# SAC0_455.0.8_config4 register map
Vendor: Texas Instruments
Peripheral module from a debugger description file (folder msp430).
Registers are 16-bit, read-write, no defined reset value unless marked. A register's access mark holds for its fields unless they carry their own. Offsets are as the file gives them; lines under a group give offsets from that group; [hi:lo] are bit positions; {n}, {i} and the like mark numbered series; 'fields as' and 'values as' point back to an identical list; <NAME> marks a mode.

## SAC0
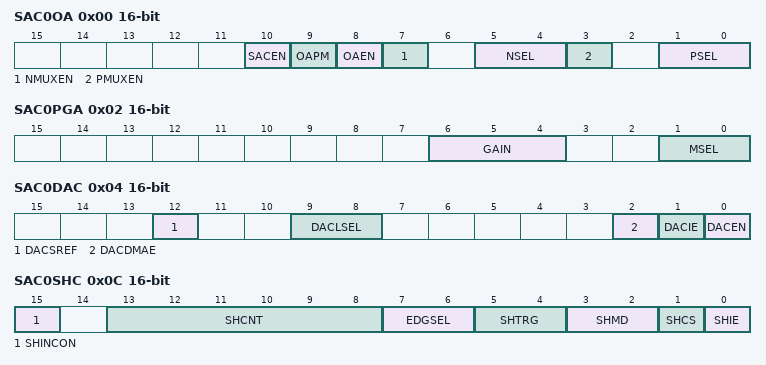
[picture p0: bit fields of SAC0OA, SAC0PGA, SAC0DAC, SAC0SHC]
0x00 SAC0OA — SAC OA Control Register
  [10] SACEN — SAC Enable selection
    0=SAC all modules are disabled, then the SAC output high impedance; 1=SAC all modules are enabled, normal mode
  [9] OAPM — SAC OA power mode selection
    0=High speed and high power; 1=Llow speed and low power
  [8] OAEN — SAC OA Enable selection
    0=SAC OA is disabled, then the SAC OA output high impedance; 1=SAC OA is enabled, normal mode
  [7] NMUXEN — SAC Negative input MUX controL
    0=All negative input sources are disconnected to OA negative port; 1=All negative input sources are connected to OA negative port
  [5:4] NSEL — SAC OA Negative input source selection
    0=External source selected; 1=PGA source selected; 2=Device Specific
  [3] PMUXEN — SAC Positive input MUX control.
    0=All positive input sources are disconnected to OA positive port; 1=All positive input sources are connected to OA positive port
  [1:0] PSEL — SAC OA Positive input source selection
    0=External source selected; 1=12-bit reference DAC source selected; 2=Pair OA source selected
0x02 SAC0PGA — SAC PGA Control Register
  [6:4] GAIN — SAC PGA Gain configuration
  [1:0] MSEL — SAC PGA Mode Selection
    0=Inverting PGA mode (external pad IN- is selected); 1=Buffer mode (floating is selected ); 2=Non-inverting mode; 3=Cascade OA Inverting mode
0x04 SAC0DAC — SAC DAC Control Register
  [12] DACSREF — SAC DAC select reference voltage
    0=AVCC; 1=Alternative reference
  [9:8] DACLSEL — SAC DAC load select. Selects the load trigger for the DAC latch.
    0=DAC latch loads when DACDAT written; 2=Device specific 0. DAC always loads data from DACDAT at the positive edge of this signal; 3=Device specific 1. DAC always loads data from DACDAT at the positive edge of this signal
  [2] DACDMAE — SAC DAC DMA request enable
    0=DMA request disabled; 1=DMA request enabled
  [1] DACIE — SAC DAC interrupt enable
    0=Disabled; 1=Enabled
  [0] DACEN — SAC DAC enable
    0=Disabled; 1=Enabled
0x06 SAC0DAT — SAC DAC Data Register
  [11:0] DACData — SAC DAC data in unsigned format.
0x08 SAC0DACSTS — SAC DAC Status Register
  [0] DACIFG — SAC DAC data update flag
0x0A SAC0IV ro — SAC Interrupt Vector Register
  [15:0] SACIV0
    0=SACIV_0 (No interrupt pending); 2=SACIV_2 (S&H completed interrupt flag (Highest priority)); 4=SACIV_4 (DAC channel update interrupt flag)
0x0C SAC0SHC — SAC S&H Circuitry Register
  [15] SHINCON — SAC S&H internal connector switch control
    0=Internal connector switch is off; 1=Internal connector switch is on
  [13:8] SHCNT — SAC S&H Counter
  [7:6] EDGSEL — SAC S&H Trigger source Edge select.
    0=Rising edge is selected; 1=Falling edge is selected; 2=Either rising or falling edge is selected
  [5:4] SHTRG — SAC S&H Trigger source select
    0=External source is selected; 1=Internal Timer is selected; 2=Device Specific; 3=Bypass
  [3:2] SHMD — SAC S&H mode select.
    0=S&H interrupt enabled; 1=S&H Channel 1 enabled; 2=S&H Channel 2 enabled; 3=S&H Channel 1 and 2 enabled
  [1] SHCS — SAC Counter Clock source selection
  [0] SHIE — SAC S&H interrupt enable.
    0=S&H interrupt disabled; 1=S&H interrupt enabled
0x0E SAC0SHSTS — SAC S&H Status Register
  [0] SHIFG — SAC S&H completed flag
    0=No S&H interrupt; 1=S&H interrupt present
